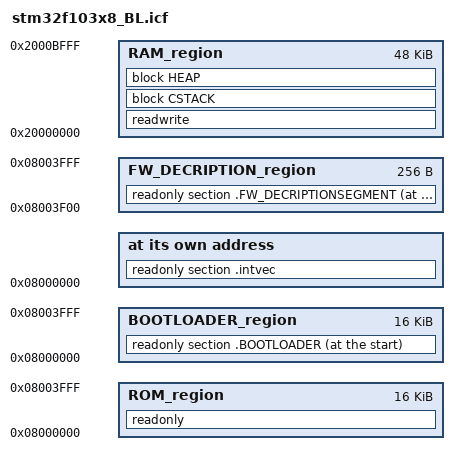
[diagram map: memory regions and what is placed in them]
/*###ICF### Section handled by ICF editor, don't touch! ****/
/*-Editor annotation file-*/
/* IcfEditorFile="$TOOLKIT_DIR$\config\ide\IcfEditor\cortex_v1_0.xml" */

define symbol __FLASH_BASE_ADDR__                               = 0x08000000;
define symbol __FLASH_END_ADDR__                                = 0x0800FFFF;/* FLASH SIZE 64 KB */
define symbol __FLASH_SIZE                                      = __FLASH_END_ADDR__ - __FLASH_BASE_ADDR__;

/*-Bootloader Regions-*/
define symbol __BOOTLOADER_START_ADDR_OFFSET__                    = 0x00000000;
define symbol __BOOTLOADER_END_ADDR_OFFSET__                      = 0x00003FFF;
define symbol __BOOTLOADER_SIZE__                                 = __BOOTLOADER_END_ADDR_OFFSET__ - __BOOTLOADER_START_ADDR_OFFSET__ + 1;

define symbol __BOOTLOADER_START_ADDR__                           = __FLASH_BASE_ADDR__ + __BOOTLOADER_START_ADDR_OFFSET__;
define symbol __BOOTLOADER_END_ADDR__                             = __FLASH_BASE_ADDR__ + __BOOTLOADER_END_ADDR_OFFSET__ ;

/*-Firmware Decription Regions-*/
define symbol __FIRMWARE_DECRIPTION_SIZE__                      = 0x0100;/*Size 256 bytes*/
define symbol __FIRMWARE_DECRIPTION_START_ADDR_OFFSET__         = __BOOTLOADER_END_ADDR_OFFSET__ - __FIRMWARE_DECRIPTION_SIZE__ + 1;
define symbol __FIRMWARE_DECRIPTION_END_ADDR_OFFSET__           = __FIRMWARE_DECRIPTION_START_ADDR_OFFSET__ + __FIRMWARE_DECRIPTION_SIZE__ - 1;

define symbol __FIRMWARE_DECRIPTION_START_ADDR__                = __FLASH_BASE_ADDR__ + __FIRMWARE_DECRIPTION_START_ADDR_OFFSET__;
define symbol __FIRMWARE_DECRIPTION_END_ADDR__                  = __FLASH_BASE_ADDR__ + __FIRMWARE_DECRIPTION_END_ADDR_OFFSET__;

/*-Memory Regions-*/
define symbol __ICFEDIT_region_ROM_start__ = __BOOTLOADER_START_ADDR__;
define symbol __ICFEDIT_region_ROM_end__   = __BOOTLOADER_END_ADDR__;
define symbol __ICFEDIT_region_RAM_start__ = 0x20000000;
define symbol __ICFEDIT_region_RAM_end__   = 0x2000BFFF;

/*-Specials-*/
define symbol __ICFEDIT_intvec_start__ = __ICFEDIT_region_ROM_start__;

/*-Sizes-*/
define symbol __ICFEDIT_size_cstack__ = 0x400;
define symbol __ICFEDIT_size_heap__   = 0x400;
/**** End of ICF editor section. ###ICF###*/

define memory mem with size = 4G;
define region ROM_region   = mem:[from __ICFEDIT_region_ROM_start__   to __ICFEDIT_region_ROM_end__];
define region RAM_region   = mem:[from __ICFEDIT_region_RAM_start__   to __ICFEDIT_region_RAM_end__];
define region BOOTLOADER_region   = mem:[from __BOOTLOADER_START_ADDR__   to __BOOTLOADER_END_ADDR__];
define region FW_DECRIPTION_region   = mem:[from __FIRMWARE_DECRIPTION_START_ADDR__   to __FIRMWARE_DECRIPTION_END_ADDR__];

define block CSTACK    with alignment = 8, size = __ICFEDIT_size_cstack__   { };
define block HEAP      with alignment = 8, size = __ICFEDIT_size_heap__     { };

initialize by copy { readwrite };
do not initialize  { section .noinit };

place at address mem:__ICFEDIT_intvec_start__ { readonly section .intvec };

place in ROM_region   { readonly };
place in RAM_region   { readwrite,
                        block CSTACK, block HEAP };
place at start of BOOTLOADER_region { readonly section .BOOTLOADER};                         
place at start of FW_DECRIPTION_region { readonly section .FW_DECRIPTIONSEGMENT}; 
